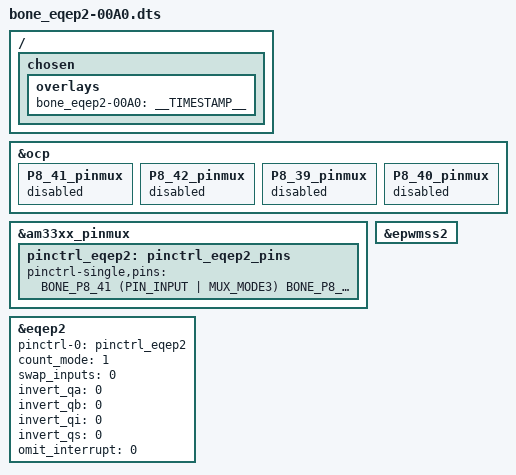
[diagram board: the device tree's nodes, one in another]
/*
 * Copyright (C) 2013 Nathaniel R. Lewis - http://nathanielrlewis.com/
 *
 * This program is free software; you can redistribute it and/or modify
 * it under the terms of the GNU General Public License version 2 as
 * published by the Free Software Foundation.
 *
 * Enable eQEP2 on the Beaglebone White and Black
 */
/dts-v1/;
/plugin/;

#include <dt-bindings/board/am335x-bbw-bbb-base.h>
#include <dt-bindings/gpio/gpio.h>
#include <dt-bindings/pinctrl/am33xx.h>

/ {
	/*
	 * Helper to show loaded overlays under: /proc/device-tree/chosen/overlays/
	 */
	fragment@0 {
		target-path="/";
		__overlay__ {

			chosen {
				overlays {
					bone_eqep2-00A0 = __TIMESTAMP__;
				};
			};
		};
	};

	/*
	 * Free up the pins used by the cape from the pinmux helpers.
	 */
	fragment@1 {
		target = <&ocp>;
		__overlay__ {
			P8_41_pinmux { status = "disabled"; };	/* P8_41: GPIO2_10 = EQEP2A_in */
			P8_42_pinmux { status = "disabled"; };	/* P8_42: GPIO2_11 = EQEP2B_in */
			P8_39_pinmux { status = "disabled"; };	/* P8_39: GPIO2_12 = EQEP2_index */
			P8_40_pinmux { status = "disabled"; };	/* P8_40: GPIO2_13 = EQEP2_strobe */
		};
	};

	fragment@2 {
		target = <&am33xx_pinmux>;
		__overlay__ {
			pinctrl_eqep2: pinctrl_eqep2_pins {
				pinctrl-single,pins = <
					BONE_P8_41 (PIN_INPUT | MUX_MODE3)	/* P8_41: GPIO2_10 = EQEP2A_in */
					BONE_P8_42 (PIN_INPUT | MUX_MODE3)	/* P8_42: GPIO2_11 = EQEP2B_in */
					BONE_P8_39 (PIN_INPUT | MUX_MODE3)	/* P8_39: GPIO2_12 = EQEP2_index */
					BONE_P8_40 (PIN_INPUT | MUX_MODE3)	/* P8_40: GPIO2_13 = EQEP2_strobe */
				>;
			};
		};
	};

	fragment@3 {
		target = <&epwmss2>;
		__overlay__ {
			status = "okay";
		};
	};

	fragment@4 {
		target = <&eqep2>;
		__overlay__ {
			pinctrl-names = "default";
			pinctrl-0 = <&pinctrl_eqep2>;

			count_mode = <1>;	// count_mode is not userspace op_mode
			// 0 -> Quadrature mode, normal 90 phase offset cha & chb.
			// 1 -> Direction mode.  cha input = clock, chb input = direction
			// 2 -> UP count mode for frequency measurement QDIR=1, ignore direction input
			// 3 -> DOWN count mode for frequency measurement QDIR=0, ignore direction input

			swap_inputs = <0>;	// swap channel A and B? (0 - no, 1 - yes)
			invert_qa = <0>;	// invert channel A input?
			invert_qb = <0>;	// invert channel B input?
			invert_qi = <0>;	// invert index input?
			invert_qs = <0>;	// invert strobe input?
			omit_interrupt = <0>;	// 1 -> do not install interrupt handler, 0 -> do install

			status = "okay";
		};
	};
};
